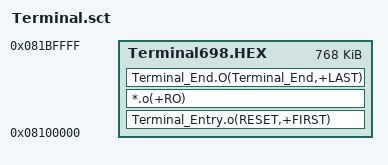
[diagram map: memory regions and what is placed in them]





LOAD_Terminal698 0x08100000 0xc0000;
{
  Terminal698.HEX 0x08100000 0xc0000;
  {
;//Entry
		Terminal_Entry.o(RESET,+FIRST)
		
		
    *.o(+RO)
		
;//End
		Terminal_End.O(Terminal_End,+LAST)	
  }
	
}









